# STM32L431VCT7 register map
File version: 1.0
Registers are 32-bit, access not given, reset 0x0 unless marked. A register's access mark holds for its fields unless they carry their own. Offsets are from the block's base; [hi:lo] are bit positions; {n}, {i} and the like mark numbered series; 'fields as' and 'values as' point back to an identical list.

## SAI1
Base 0x40015400
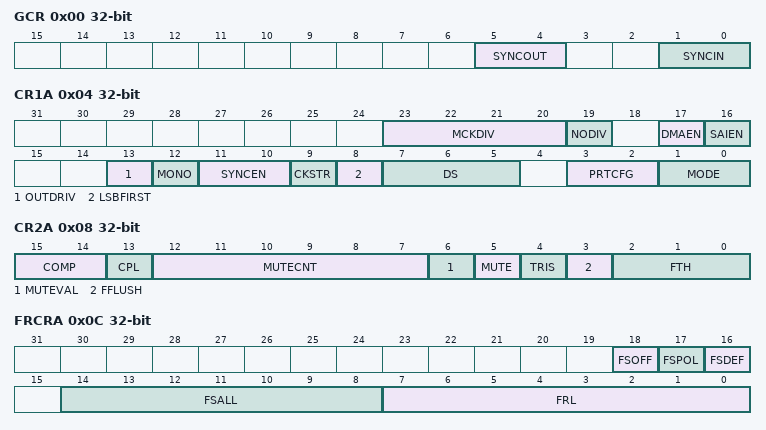
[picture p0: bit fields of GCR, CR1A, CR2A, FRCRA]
0x00 GCR
  [5:4] SYNCOUT, [1:0] SYNCIN
0x04 CR1A
  [23:20] MCKDIV, [19] NODIV, [17] DMAEN, [16] SAIEN, [13] OUTDRIV, [12] MONO, [11:10] SYNCEN, [9] CKSTR, [8] LSBFIRST, [7:5] DS, [3:2] PRTCFG, [1:0] MODE
0x08 CR2A
  [15:14] COMP, [13] CPL, [12:7] MUTECNT, [6] MUTEVAL, [5] MUTE, [4] TRIS, [3] FFLUSH, [2:0] FTH
0x0C FRCRA
  [18] FSOFF, [17] FSPOL, [16] FSDEF, [14:8] FSALL, [7:0] FRL
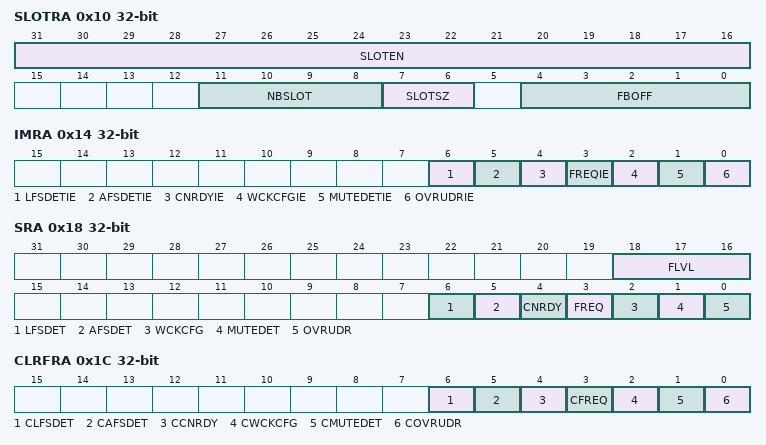
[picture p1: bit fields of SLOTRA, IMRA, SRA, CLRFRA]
0x10 SLOTRA
  [31:16] SLOTEN, [11:8] NBSLOT, [7:6] SLOTSZ, [4:0] FBOFF
0x14 IMRA
  [6] LFSDETIE, [5] AFSDETIE, [4] CNRDYIE, [3] FREQIE, [2] WCKCFGIE, [1] MUTEDETIE, [0] OVRUDRIE
0x18 SRA
  [18:16] FLVL, [6] LFSDET, [5] AFSDET, [4] CNRDY, [3] FREQ, [2] WCKCFG, [1] MUTEDET, [0] OVRUDR
0x1C CLRFRA
  [6] CLFSDET, [5] CAFSDET, [4] CCNRDY, [3] CFREQ, [2] CWCKCFG, [1] CMUTEDET, [0] COVRUDR
0x20 DRA
  [31:0] DATA
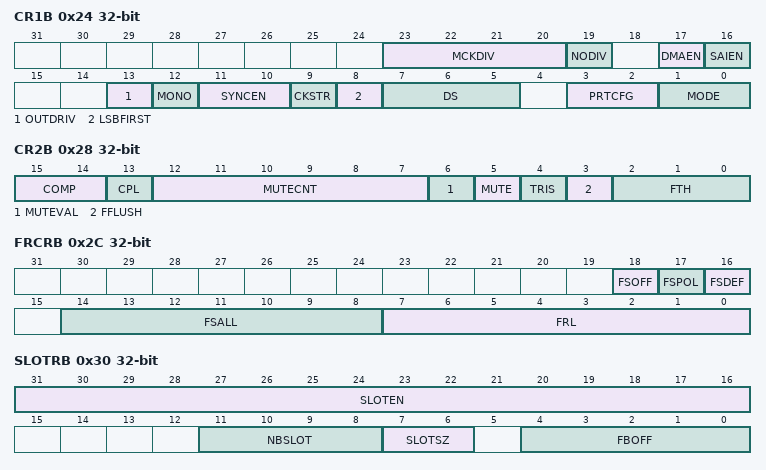
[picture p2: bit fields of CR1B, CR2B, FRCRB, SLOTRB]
0x24 CR1B
  fields as CR1A
0x28 CR2B
  fields as CR2A
0x2C FRCRB
  [18] FSOFF, [17] FSPOL, [16] FSDEF, [14:8] FSALL, [7:0] FRL
0x30 SLOTRB
  [31:16] SLOTEN, [11:8] NBSLOT, [7:6] SLOTSZ, [4:0] FBOFF
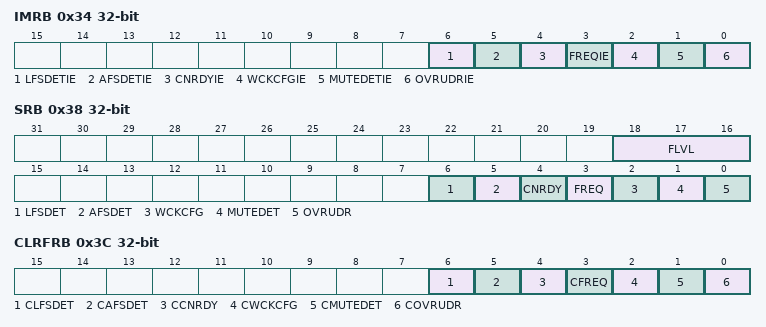
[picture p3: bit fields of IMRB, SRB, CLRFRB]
0x34 IMRB
  fields as IMRA
0x38 SRB
  fields as SRA
0x3C CLRFRB
  fields as CLRFRA
0x40 DRB
  [31:0] DATA

## DMA1
Base 0x40020000
Same registers: DMA2 0x40020400
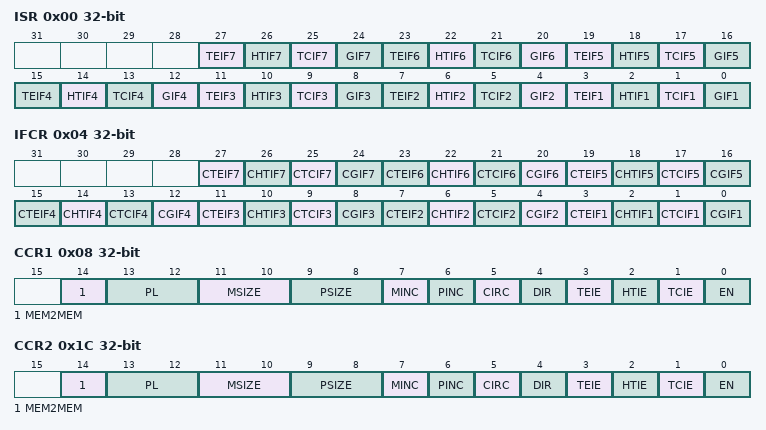
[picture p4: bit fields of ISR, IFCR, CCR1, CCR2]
0x00 ISR
  [4n-1] TEIF{n} (n=1..7), [4n-2] HTIF{n} (n=1..7), [4n-3] TCIF{n} (n=1..7), [4n-4] GIF{n} (n=1..7)
0x04 IFCR
  [4n-1] CTEIF{n} (n=1..7), [4n-2] CHTIF{n} (n=1..7), [4n-3] CTCIF{n} (n=1..7), [4n-4] CGIF{n} (n=1..7)
0x08 CCR1
  [14] MEM2MEM, [13:12] PL, [11:10] MSIZE, [9:8] PSIZE, [7] MINC, [6] PINC, [5] CIRC, [4] DIR, [3] TEIE, [2] HTIE, [1] TCIE, [0] EN
0x0C CNDTR1
  [15:0] NDT
0x10 CPAR1
  [31:0] PA
{0x0+0x14*i} CMAR{i} (i=1..7)
  [31:0] MA
0x1C CCR2
  fields as CCR1
0x20 CNDTR2
  [15:0] NDT
0x24 CPAR2
  [31:0] PA
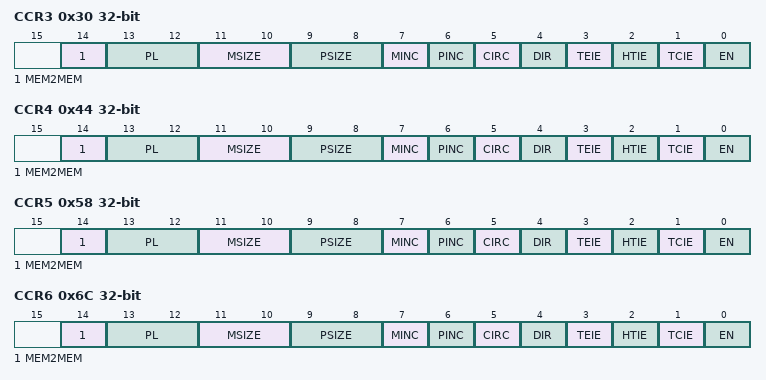
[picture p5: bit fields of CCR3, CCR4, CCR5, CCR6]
0x30 CCR3
  fields as CCR1
0x34 CNDTR3
  [15:0] NDT
0x38 CPAR3
  [31:0] PA
0x44 CCR4
  fields as CCR1
0x48 CNDTR4
  [15:0] NDT
0x4C CPAR4
  [31:0] PA
0x58 CCR5
  fields as CCR1
0x5C CNDTR5
  [15:0] NDT
0x60 CPAR5
  [31:0] PA
0x6C CCR6
  fields as CCR1
0x70 CNDTR6
  [15:0] NDT
0x74 CPAR6
  [31:0] PA
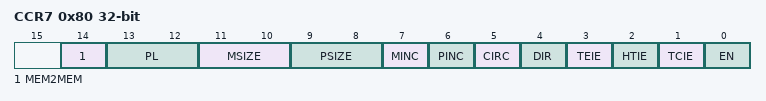
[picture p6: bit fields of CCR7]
0x80 CCR7
  fields as CCR1
0x84 CNDTR7
  [15:0] NDT
0x88 CPAR7
  [31:0] PA

## DMA1_CSELR
Base 0x400200A8
Same registers: DMA2_CSELR 0x400204A8
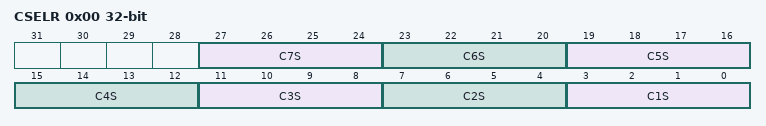
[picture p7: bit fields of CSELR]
0x00 CSELR
  [4n-1:4n-4] C{n}S (n=1..7)

## FLASH
Base 0x40022000
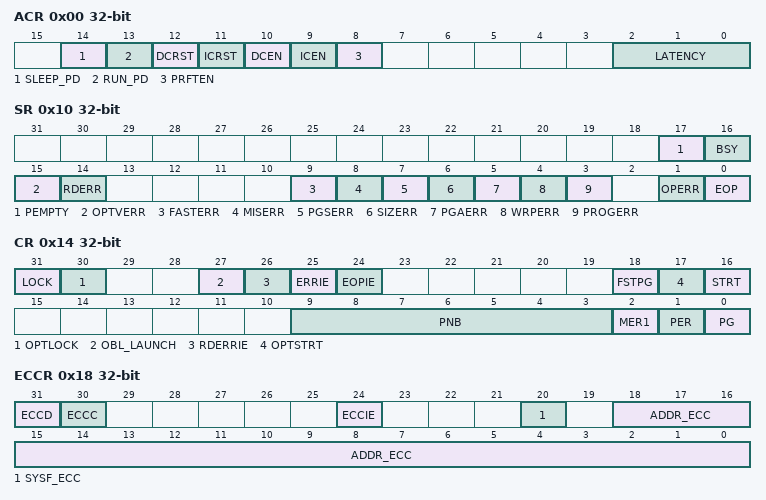
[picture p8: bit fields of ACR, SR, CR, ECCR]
0x00 ACR
  [14] SLEEP_PD, [13] RUN_PD, [12] DCRST, [11] ICRST, [10] DCEN, [9] ICEN, [8] PRFTEN, [2:0] LATENCY
0x04 PDKEYR
0x08 KEYR
0x0C OPTKEYR
0x10 SR
  [17] PEMPTY, [16] BSY, [15] OPTVERR, [14] RDERR, [9] FASTERR, [8] MISERR, [7] PGSERR, [6] SIZERR, [5] PGAERR, [4] WRPERR, [3] PROGERR, [1] OPERR, [0] EOP
0x14 CR
  [31] LOCK, [30] OPTLOCK, [27] OBL_LAUNCH, [26] RDERRIE, [25] ERRIE, [24] EOPIE, [18] FSTPG, [17] OPTSTRT, [16] STRT, [9:3] PNB, [2] MER1, [1] PER, [0] PG
0x18 ECCR
  [31] ECCD, [30] ECCC, [24] ECCIE, [20] SYSF_ECC, [18:0] ADDR_ECC
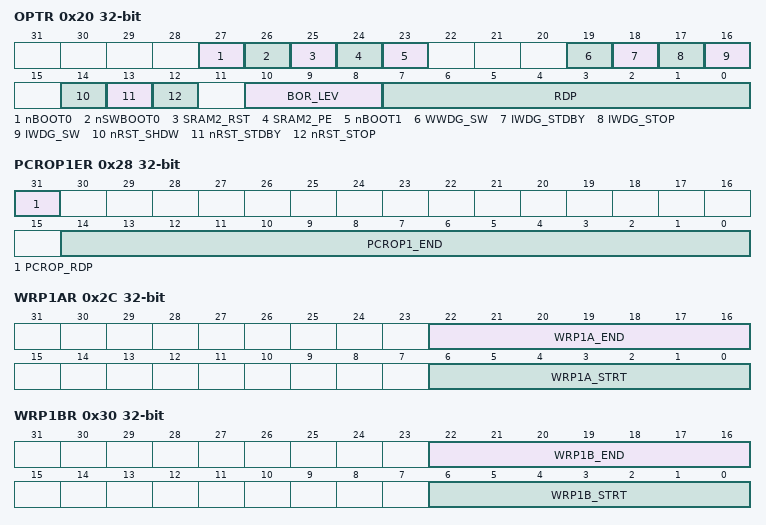
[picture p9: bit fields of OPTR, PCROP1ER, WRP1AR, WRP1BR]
0x20 OPTR
  [27] nBOOT0, [26] nSWBOOT0, [25] SRAM2_RST, [24] SRAM2_PE, [23] nBOOT1, [19] WWDG_SW, [18] IWDG_STDBY, [17] IWDG_STOP, [16] IWDG_SW, [14] nRST_SHDW, [13] nRST_STDBY, [12] nRST_STOP, [10:8] BOR_LEV, [7:0] RDP
0x24 PCROP1SR
  [14:0] PCROP1_STRT
0x28 PCROP1ER
  [31] PCROP_RDP, [14:0] PCROP1_END
0x2C WRP1AR
  [22:16] WRP1A_END, [6:0] WRP1A_STRT
0x30 WRP1BR
  [22:16] WRP1B_END, [6:0] WRP1B_STRT

## CRC
Base 0x40023000
0x00 DR
0x04 IDR 8-bit
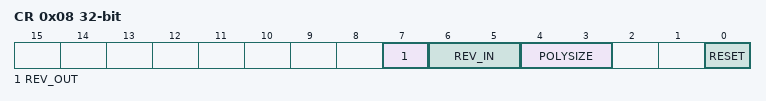
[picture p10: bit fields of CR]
0x08 CR
  [7] REV_OUT, [6:5] REV_IN, [4:3] POLYSIZE, [0] RESET
0x10 INIT
0x14 POL

## TSC
Base 0x40024000
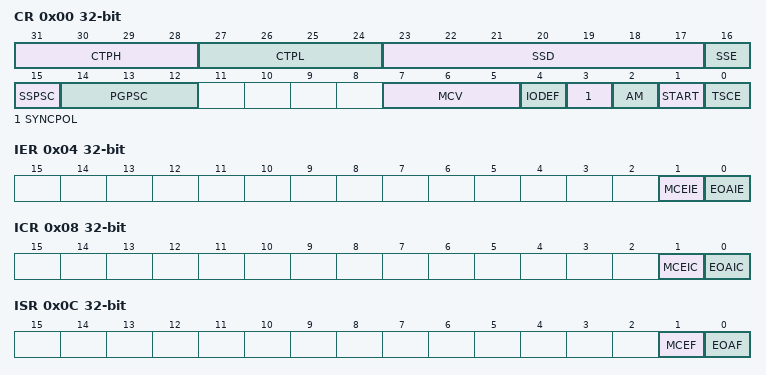
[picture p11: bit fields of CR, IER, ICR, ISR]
0x00 CR
  [31:28] CTPH, [27:24] CTPL, [23:17] SSD, [16] SSE, [15] SSPSC, [14:12] PGPSC, [7:5] MCV, [4] IODEF, [3] SYNCPOL, [2] AM, [1] START, [0] TSCE
0x04 IER
  [1] MCEIE, [0] EOAIE
0x08 ICR
  [1] MCEIC, [0] EOAIC
0x0C ISR
  [1] MCEF, [0] EOAF
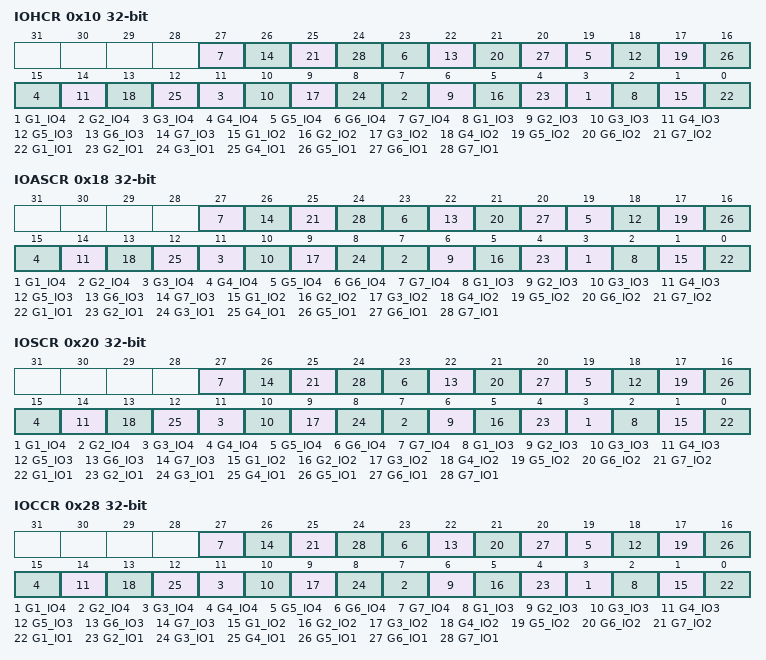
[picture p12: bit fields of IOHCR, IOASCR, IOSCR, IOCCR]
0x10 IOHCR
  [4n-1] G{n}_IO4 (n=1..7), [4n-2] G{n}_IO3 (n=1..7), [4n-3] G{n}_IO2 (n=1..7), [4n-4] G{n}_IO1 (n=1..7)
0x18 IOASCR
  fields as IOHCR
0x20 IOSCR
  fields as IOHCR
0x28 IOCCR
  fields as IOHCR
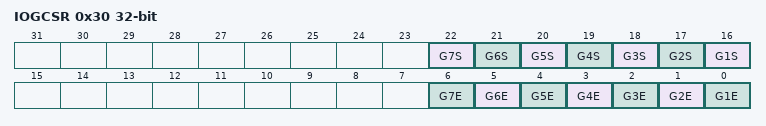
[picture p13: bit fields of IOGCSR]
0x30 IOGCSR
  [n+15] G{n}S (n=1..7), [n-1] G{n}E (n=1..7)
0x34 IOGXCR.0
  [13:0] CNT
0x38 IOGXCR.1
  [13:0] CNT
0x3C IOGXCR.2
  [13:0] CNT
0x40 IOGXCR.3
  [13:0] CNT
0x44 IOGXCR.4
  [13:0] CNT
0x48 IOGXCR.5
  [13:0] CNT
0x4C IOGXCR.6
  [13:0] CNT

## GPIOA
Base 0x48000000
Same registers: GPIOB 0x48000400, GPIOC 0x48000800, GPIOD 0x48000C00, GPIOE 0x48001000, GPIOH 0x48001C00
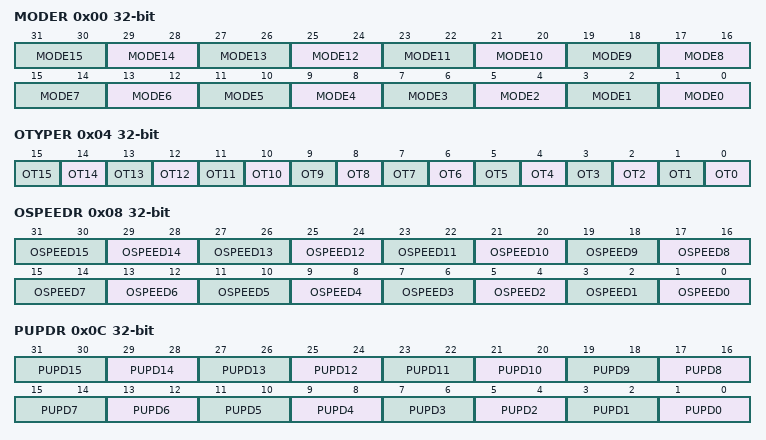
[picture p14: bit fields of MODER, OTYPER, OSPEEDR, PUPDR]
0x00 MODER
  [2n+1:2n] MODE{n} (n=0..15)
0x04 OTYPER
  [n] OT{n} (n=0..15)
0x08 OSPEEDR
  [2n+1:2n] OSPEED{n} (n=0..15)
0x0C PUPDR
  [2n+1:2n] PUPD{n} (n=0..15)
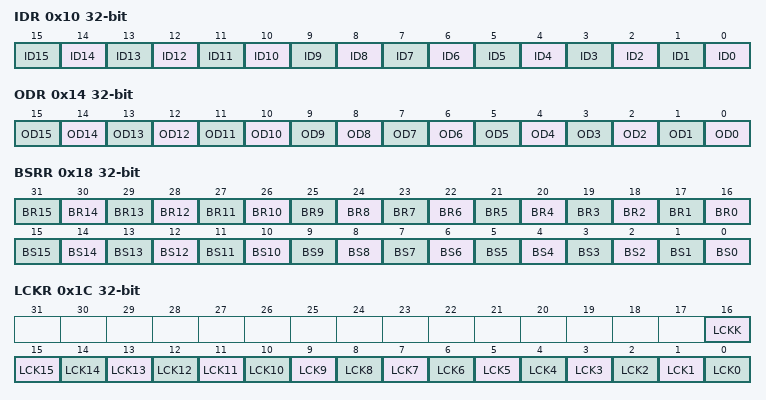
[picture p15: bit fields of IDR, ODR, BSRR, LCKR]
0x10 IDR
  [n] ID{n} (n=0..15)
0x14 ODR
  [n] OD{n} (n=0..15)
0x18 BSRR
  [n+16] BR{n} (n=0..15), [n] BS{n} (n=0..15)
0x1C LCKR
  [16] LCKK, [n] LCK{n} (n=0..15)
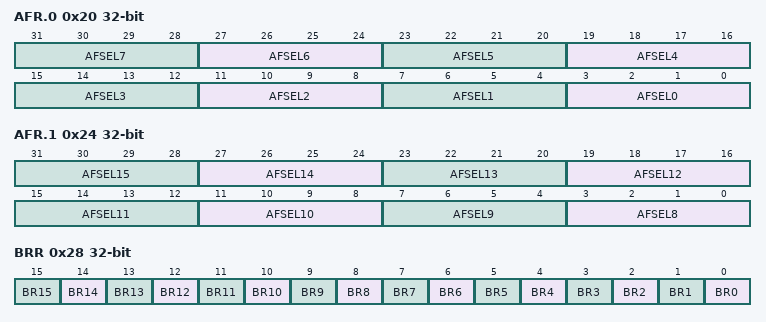
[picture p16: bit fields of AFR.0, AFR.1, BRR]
0x20 AFR.0
  [4n+3:4n] AFSEL{n} (n=0..7)
0x24 AFR.1
  [4n-29:4n-32] AFSEL{n} (n=8..15)
0x28 BRR
  [n] BR{n} (n=0..15)

## ADC1
Base 0x50040000
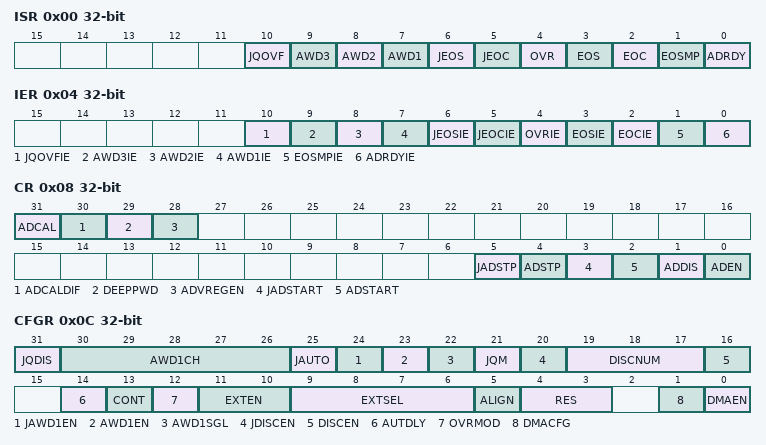
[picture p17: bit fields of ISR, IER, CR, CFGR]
0x00 ISR
  [10] JQOVF, [9] AWD3, [8] AWD2, [7] AWD1, [6] JEOS, [5] JEOC, [4] OVR, [3] EOS, [2] EOC, [1] EOSMP, [0] ADRDY
0x04 IER
  [10] JQOVFIE, [9] AWD3IE, [8] AWD2IE, [7] AWD1IE, [6] JEOSIE, [5] JEOCIE, [4] OVRIE, [3] EOSIE, [2] EOCIE, [1] EOSMPIE, [0] ADRDYIE
0x08 CR
  [31] ADCAL, [30] ADCALDIF, [29] DEEPPWD, [28] ADVREGEN, [5] JADSTP, [4] ADSTP, [3] JADSTART, [2] ADSTART, [1] ADDIS, [0] ADEN
0x0C CFGR
  [31] JQDIS, [30:26] AWD1CH, [25] JAUTO, [24] JAWD1EN, [23] AWD1EN, [22] AWD1SGL, [21] JQM, [20] JDISCEN, [19:17] DISCNUM, [16] DISCEN, [14] AUTDLY, [13] CONT, [12] OVRMOD, [11:10] EXTEN, [9:6] EXTSEL, [5] ALIGN, [4:3] RES, [1] DMACFG, [0] DMAEN
0x10 CFGR2
  [10] ROVSM, [9] TROVS, [8:5] OVSS, [4:2] OVSR, [1] JOVSE, [0] ROVSE
0x14 SMPR1
  [3n+2:3n] SMP{n} (n=0..9)
0x18 SMPR2
  [3n-28:3n-30] SMP{n} (n=10..18)
0x20 TR1
  [27:16] HT1, [11:0] LT1
0x24 TR2
  [23:16] HT2, [7:0] LT2
0x28 TR3
  [23:16] HT3, [7:0] LT3
0x30 SQR1
  [6n+4:6n] SQ{n} (n=1..4), [3:0] L
0x34 SQR2
  [6n-26:6n-30] SQ{n} (n=5..9)
0x38 SQR3
  [6n-56:6n-60] SQ{n} (n=10..14)
0x3C SQR4
  [10:6] SQ16, [4:0] SQ15
0x40 DR
  [15:0] RDATA
0x4C JSQR
  [6n+6:6n+2] JSQ{n} (n=1..4), [7:6] JEXTEN, [5:2] JEXTSEL, [1:0] JL
{0x5C+4i} OFR{i} (i=1..4)
  [31] OFFSET{i}_EN, [30:26] OFFSET{i}_CH, [11:0] OFFSET{i}
{0x7C+4i} JDR{i} (i=1..4)
  [15:0] JDATA
0xA0 AWD2CR
  [18:0] AWD2CH
0xA4 AWD3CR
  [18:0] AWD3CH
0xB0 DIFSEL
  [18:0] DIFSEL
0xB4 CALFACT
  [22:16] CALFACT_D, [6:0] CALFACT_S
0x308 CCR
  [24] VBATEN, [23] TSEN, [22] VREFEN, [21:18] PRESC, [17:16] CKMODE

## RNG
Base 0x50060800
0x00 CR
  [3] IE, [2] RNGEN
0x04 SR
  [6] SEIS, [5] CEIS, [2] SECS, [1] CECS, [0] DRDY
0x08 DR

## QUADSPI
Base 0xA0001000
0x00 CR
  [31:24] PRESCALER, [23] PMM, [22] APMS, [20] TOIE, [19] SMIE, [18] FTIE, [17] TCIE, [16] TEIE, [11:8] FTHRES, [7] FSEL, [6] DFM, [4] SSHIFT, [3] TCEN, [2] DMAEN, [1] ABORT, [0] EN
0x04 DCR
  [20:16] FSIZE, [10:8] CSHT, [0] CKMODE
0x08 SR
  [12:8] FLEVEL, [5] BUSY, [4] TOF, [3] SMF, [2] FTF, [1] TCF, [0] TEF
0x0C FCR
  [4] CTOF, [3] CSMF, [1] CTCF, [0] CTEF
0x10 DLR
  [31:0] DL
0x14 CCR
  [31] DDRM, [30] DHHC, [28] SIOO, [27:26] FMODE, [25:24] DMODE, [22:18] DCYC, [17:16] ABSIZE, [15:14] ABMODE, [13:12] ADSIZE, [11:10] ADMODE, [9:8] IMODE, [7:0] INSTRUCTION
0x18 AR
  [31:0] ADDRESS
0x1C ABR
  [31:0] ALTERNATE
0x20 DR
  [31:0] DATA
0x24 PSMKR
  [31:0] MASK
0x28 PSMAR
  [31:0] MATCH
0x2C PIR
  [15:0] INTERVAL
0x30 LPTR
  [15:0] TIMEOUT

## DBGMCU
Base 0xE0042000
0x00 IDCODE
  [31:16] REV_ID, [11:0] DEV_ID
0x04 CR
  [7:6] TRACE_MODE, [5] TRACE_IOEN, [2] DBG_STANDBY, [1] DBG_STOP, [0] DBG_SLEEP
0x08 APB1FZR1
  [31] DBG_LPTIM1_STOP, [25] DBG_CAN_STOP, [23] DBG_I2C3_STOP, [22] DBG_I2C2_STOP, [21] DBG_I2C1_STOP, [12] DBG_IWDG_STOP, [11] DBG_WWDG_STOP, [10] DBG_RTC_STOP, [5] DBG_TIM7_STOP, [4] DBG_TIM6_STOP, [0] DBG_TIM2_STOP
0x0C APB1FZR2
  [5] DBG_LPTIM2_STOP
0x10 APB2FZ
  [17] DBG_TIM16_STOP, [16] DBG_TIM15_STOP, [11] DBG_TIM1_STOP
